VERSION ""

NS_ :

BS_:

BU_: BCM LCM COMBI
VAL_TABLE_ Ignition_Val_Table 5 "Not_Available" 4 "Error" 3 "Start" 2 "ON" 1 "Accessory" 0 "OFF" ;
VAL_TABLE_ Highbeam_Lig_Val_Table 3 "Not_Available" 2 "Error" 1 "Highbeam_Lig_ON" 0 "Highbeam_Lig_OFF" ;
VAL_TABLE_ Lowbeam_Lig_Val_Table 3 "Not Avialable" 2 "Error" 1 "Lowbeam_Lig_ON" 0 "Lowbeam_Lig_OFF" ;
VAL_TABLE_ position_lig_val_table 3 "Not Avialable" 2 "Error" 1 "Position_light_ON" 0 "Position_light_OFF" ;

BO_ 292 Ignition_Input: 1 BCM
 SG_ Ignition_Input_Siganl : 0|3@1- (1,0) [0|5] "" Vector__XXX

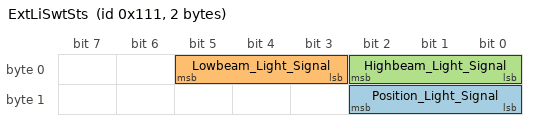
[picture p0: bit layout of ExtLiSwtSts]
BO_ 273 ExtLiSwtSts: 2 COMBI
 SG_ Position_Light_Signal : 8|3@1- (1,0) [0|4] "" Vector__XXX
 SG_ Lowbeam_Light_Signal : 3|3@1- (1,0) [0|4] "" Vector__XXX
 SG_ Highbeam_Light_Signal : 0|3@1- (1,0) [0|4] "" Vector__XXX

BA_DEF_  "BusType" STRING ;
BA_DEF_DEF_  "BusType" "CAN";
VAL_ 292 Ignition_Input_Siganl 5 "Not_Available" 4 "Error" 3 "Start" 2 "ON" 1 "Accessory" 0 "OFF" ;
VAL_ 273 Position_Light_Signal 3 "Not Avialable" 2 "Error" 1 "Position_light_ON" 0 "Position_light_OFF" ;
VAL_ 273 Lowbeam_Light_Signal 3 "Not Avialable" 2 "Error" 1 "Lowbeam_Lig_ON" 0 "Lowbeam_Lig_OFF" ;
VAL_ 273 Highbeam_Light_Signal 3 "Not_Available" 2 "Error" 1 "Highbeam_Lig_ON" 0 "Highbeam_Lig_OFF" ;
